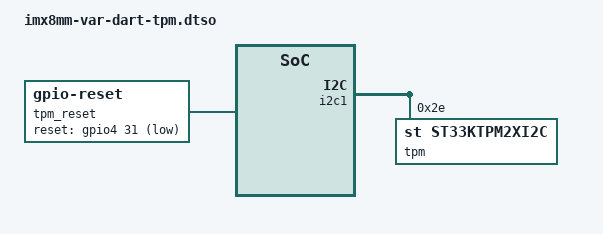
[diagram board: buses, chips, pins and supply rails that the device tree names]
// SPDX-License-Identifier: (GPL-2.0+ OR MIT)
/*
 * Device tree overlay for the TPM on DART-MX8M-MINI 3.x modules.
 *
 * Copyright 2026 Variscite Ltd.
 */

/dts-v1/;
/plugin/;

#include <dt-bindings/gpio/gpio.h>
#include "imx8mm-pinfunc.h"

&{/} {
	tpm_reset: tpm-reset {
		compatible = "gpio-reset";
		#reset-cells = <0>;
		pinctrl-names = "default";
		pinctrl-0 = <&pinctrl_tpm_reset>;
		reset-gpios = <&gpio4 31 GPIO_ACTIVE_LOW>;
		initially-in-reset;
	};
};

&i2c1 {
	#address-cells = <1>;
	#size-cells = <0>;

	st33ktpm2xi2c_som: tpm@2e {
		status = "okay";
		compatible = "st,st33ktpm2xi2c", "tcg,tpm-tis-i2c";
		reg = <0x2e>;
		label = "tpm";
		resets = <&tpm_reset>;
	};
};

&iomuxc {
	pinctrl_tpm_reset: tpm-resetgrp {
		fsl,pins = <
			MX8MM_IOMUXC_SAI3_TXFS_GPIO4_IO31		0x19
		>;
	};
};
